# NUC121AE_v1 register map
File version: 1.0
Registers are 32-bit, read-write, reset 0x0 unless marked. A register's access mark holds for its fields unless they carry their own. Offsets are from the block's base; [hi:lo] are bit positions; lines under a group give offsets from that group; {n}, {i} and the like mark numbered series; 'fields as' and 'values as' point back to an identical list.

## CLK — CLK Register Map
Base 0x50000200
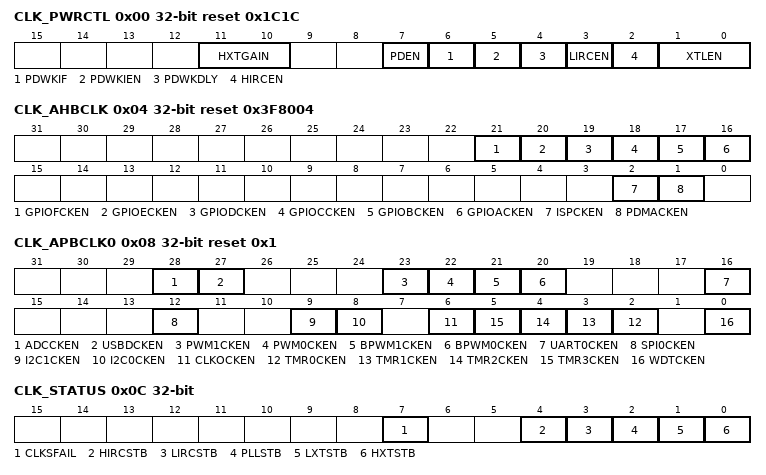
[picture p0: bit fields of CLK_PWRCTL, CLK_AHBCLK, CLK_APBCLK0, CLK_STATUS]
0x00 CLK_PWRCTL reset 0x1C1C — System Power-down Control Register
  [11:10] HXTGAIN — HXT Gain Control Bit (Write Protect). This is a protected register. Please refer to open lock sequence to program it. Gain control is used to enlarge the gain of crystal to make sure crystal work normally. If gain control is enabled, crystal will consume more power than gain control off. Note 1: These bits are write protected. Refer to the SYS_REGLCTL register. Note 2: These bits are over-written by CFGXT1 (CONFIG0[18:17]) after reset.
    0=HXT frequency is lower than from 8 MHz; 1=HXT frequency is from 8 MHz to 12 MHz; 2=HXT frequency is from 12 MHz to 16 MHz; 3=HXT frequency is higher than 16 MHz
  [7] PDEN — System Power-down Enable (Write Protect). When this bit is set to 1, Power-down mode is enabled and chip keeps active till the CPU sleep mode is also active and then the chip enters Power-down mode. When chip wakes up from Power-down mode, this bit is auto cleared. Users need to set this bit again for next Power-down. In Power-down mode, HXT and the HIRC will be disabled in this mode, but LXT and LIRC are not controlled by Power-down mode. In Power-down mode, the PLL and system clock are disabled, and ignored the clock source selection. The clocks of peripheral are not controlled by Power-down mode, if the peripheral clock source is from LXT or LIRC. Note: This bit is write protected. Refer to the SYS_REGLCTL register.
    0=Chip operating normally or chip in idle mode because of WFI command; 1=Chip enters Power-down mode instant or wait CPU sleep command WFI
  [6] PDWKIF — Power-down Mode Wake-up Interrupt Status. Set by "Power-down wake-up event", it indicates that resume from Power-down mode" The flag is set if the EINT0~5, GPIO, USBD, UART0, WDT, BOD, TMR0~3 or I2C0~1 wake-up occurred. Note1: Write 1 to clear the bit to 0. Note2: This bit works only if PDWKIEN (CLK_PWRCTL[5]) set to 1.
  [5] PDWKIEN — Power-down Mode Wake-up Interrupt Enable Bit (Write Protect). Note1: The interrupt will occur when both PDWKIF and PDWKIEN are high. Note2: This bit is write protected. Refer to the SYS_REGLCTL register.
    0=Power-down mode wake-up interrupt Disabled; 1=Power-down mode wake-up interrupt Enabled
  [4] PDWKDLY — Enable the Wake-up Delay Counter (Write Protect). When the chip wakes up from Power-down mode, the clock control will delay certain clock cycles to wait system clock stable. The delayed clock cycle is 4096 clock cycles when chip work at 4~24 MHz external high speed crystal oscillator (HXT), and 512 clock cycles(selected by HIRCSTBS) when chip work at 48 MHz internal high speed RC oscillator (HIRC). Note: This bit is write protected. Refer to the SYS_REGLCTL register.
    0=Clock cycles delay Disabled; 1=Clock cycles delay Enabled
  [3] LIRCEN — LIRC Enable Bit (Write Protect). Note: This bit is write protected. Refer to the SYS_REGLCTL register.
    0=10 kHz internal low speed RC oscillator (LIRC) Disabled; 1=10 kHz internal low speed RC oscillator (LIRC) Enabled
  [2] HIRCEN — HIRC Enable Bit (Write Protect). Note: This bit is write protected. Refer to the SYS_REGLCTL register.
    0=48 MHz internal high speed RC oscillator (HIRC) Disabled; 1=48 MHz internal high speed RC oscillator (HIRC) Enabled
  [1:0] XTLEN — External HXT or LXT Crystal Oscillator Enable Bit (Write Protect). The default clock source is from HIRC. These two bits are default set to "00" and the PF.0 and PF.1 pins are GPIO. Note 1: These bits are write protected. Refer to the SYS_REGLCTL register. Note 2: These bits are over-written by CFOSC (CONFIG0[26]) after reset.
    0=HXT LXT Disabled (default); 1=HXT Enabled; 2=LXT Enabled
0x04 CLK_AHBCLK reset 0x3F8004 — AHB Devices Clock Enable Control Register
  [21] GPIOFCKEN — General Purpose I/O PF Group Clock Enable Bit
    0=GPIO PF group clock Disabled; 1=GPIO PF group clock Enabled
  [20] GPIOECKEN — General Purpose I/O PE Group Clock Enable Bit
    0=GPIO PE group clock Disabled; 1=GPIO PE group clock Enabled
  [19] GPIODCKEN — General Purpose I/O PD Group Clock Enable Bit
    0=GPIO PD group clock Disabled; 1=GPIO PD group clock Enabled
  [18] GPIOCCKEN — General Purpose I/O PC Group Clock Enable Bit
    0=GPIO PC group clock Disabled; 1=GPIO PC group clock Enabled
  [17] GPIOBCKEN — General Purpose I/O PB Group Clock Enable Bit
    0=GPIO PB group clock Disabled; 1=GPIO PB group clock Enabled
  [16] GPIOACKEN — General Purpose I/O PA Group Clock Enable Bit
    0=GPIO PA group clock Disabled; 1=GPIO PA group clock Enabled
  [2] ISPCKEN — Flash ISP Controller Clock Enable Bit
    0=Flash ISP peripheral clock Disabled; 1=Flash ISP peripheral clock Enabled
  [1] PDMACKEN — PDMA Controller Clock Enable Bit
    0=PDMA peripheral clock Disabled; 1=PDMA peripheral clock Enabled
0x08 CLK_APBCLK0 reset 0x1 — APB Devices Clock Enable Control Register 0
  [28] ADCCKEN — Analog-digital-converter (ADC) Clock Enable Bit
    0=ADC clock Disabled; 1=ADC clock Enabled
  [27] USBDCKEN — USB Device Clock Enable Bit
    0=USB Device clock Disabled; 1=USB Device clock Enabled
  [23] PWM1CKEN — PWM1 Clock Enable Bit
    0=PWM1 clock Disabled; 1=PWM1 clock Enabled
  [22] PWM0CKEN — PWM0 Clock Enable Bit
    0=PWM0 clock Disabled; 1=PWM0 clock Enabled
  [21] BPWM1CKEN — BPWM1 Clock Enable Bit
    0=BPWM1 clock Disabled; 1=BPWM1 clock Enabled
  [20] BPWM0CKEN — BPWM0 Clock Enable Bit
    0=BPWM0 clock Disabled; 1=BPWM0 clock Enabled
  [16] UART0CKEN — UART0 Clock Enable Bit
    0=UART0 clock Disabled; 1=UART0 clock Enabled
  [12] SPI0CKEN — SPI0 Clock Enable Bit
    0=SPI0 Clock Disabled; 1=SPI0 Clock Enabled
  [9] I2C1CKEN — I2C1 Clock Enable Bit
    0=I2C1 Clock Disabled; 1=I2C1 Clock Enabled
  [8] I2C0CKEN — I2C0 Clock Enable Bit
    0=I2C0 Clock Disabled; 1=I2C0 Clock Enabled
  [6] CLKOCKEN — CLKO Clock Enable Bit
    0=CLKO Clock Disabled; 1=CLKO Clock Enabled
  [n+2] TMR{n}CKEN (n=0..3) — Timer{n} Clock Enable Bit
    0=Timer{n} Clock Disabled; 1=Timer{n} Clock Enabled
  [0] WDTCKEN — Watchdog Timer Clock Enable Bit (Write Protect). Note: This bit is write protected. Refer to the SYS_REGLCTL register.
    0=Watchdog Timer Clock Disabled; 1=Watchdog Timer Clock Enabled
0x0C CLK_STATUS ro (reset mask 0xFFFFFF00) — Clock Status Monitor Register
  [7] CLKSFAIL — Clock Switching Fail Flag (Read Only). This bit is updated when software switches system clock source. If switch target clock is stable, this bit will be set to 0. If switch target clock is not stable, this bit will be set to 1. Note 1: Clock switch will finish automatically when target clcok is stable even if this bit already set to 1.
    0=Clock switching success; 1=Clock switching failure
  [4] HIRCSTB — HIRC Clock Source Stable Flag (Read Only)
    0=48 MHz internal high speed RC oscillator (HIRC) clock is not stable or disabled; 1=48 MHz internal high speed RC oscillator (HIRC) clock is stabe and enabled
  [3] LIRCSTB — LIRC Clock Source Stable Flag (Read Only)
    0=10 kHz internal low speed RC oscillator (LIRC) clock is not stable or disabled; 1=10 kHz internal low speed RC oscillator (LIRC) clock is stable and enabled
  [2] PLLSTB — Internal PLL Clock Source Stable Flag (Read Only)
    0=Internal PLL clock is not stable or disabled; 1=Internal PLL clock is stable and enabled
  [1] LXTSTB — LXT Clock Source Stable Flag (Read Only)
    0=32.768 kHz external low speed crystal oscillator (LXT) clock is not stable or disabled; 1=32.768 kHz external low speed crystal oscillator (LXT) clock is stabled and enabled
  [0] HXTSTB — HXT Clock Source Stable Flag (Read Only)
    0=4~24 MHz external high speed crystal oscillator (HXT) clock is not stable or disabled; 1=4~24 MHz external high speed crystal oscillator (HXT)clock is stable and enabled
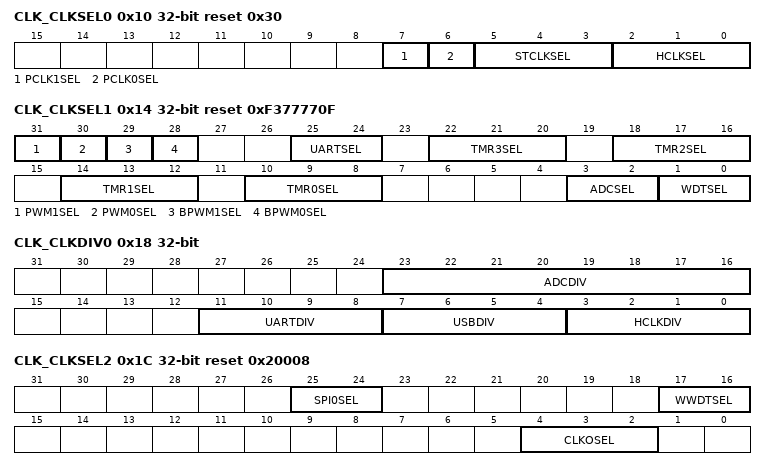
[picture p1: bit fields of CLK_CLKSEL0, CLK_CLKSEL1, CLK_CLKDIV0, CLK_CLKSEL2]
0x10 CLK_CLKSEL0 reset 0x30 (reset mask 0xFFFFFFF0) — Clock Source Select Control Register 0
  [7] PCLK1SEL — PCLK1 Clock Source Selection (Write Protect). Note: This bit is write protected. Refer to the SYS_REGLCTL register.
    0=APB1 BUS clock source from HCLK clock; 1=APB1 BUS clock source from HCLK/2
  [6] PCLK0SEL — PCLK0 Clock Source Selection (Write Protect). Note: This bit is write protected. Refer to the SYS_REGLCTL register.
    0=APB0 BUS clock source from HCLK clock; 1=APB0 BUS clock source from HCLK/2
  [5:3] STCLKSEL — Cortex-M0 SysTick Clock Source Selection (Write Protect). Note: These bits are write protected. Refer to the SYS_REGLCTL register.
    0=Clock source from HXT clock; 1=Clock source from LXT clock; 2=Clock source from HXT/2; 3=Clock source from HCLK/2; 7=Clock source from HIRC/4 (12 MHz)
  [2:0] HCLKSEL — HCLK Clock Source Selection (Write Protect). Before clock switching, the related clock sources (both pre-select and new-select) must be turned on. The default value is reloaded from the value of CFOSC (CONFIG0[26:24]) in user configuration register of Flash controller by any reset. Therefore the default value is either 000b or 111b. Note: These bits are write protected. Refer to the SYS_REGLCTL register.
    0=Clock source from HXT clock; 1=Clock source from LXT clock; 2=Clock source from PLL clock; 3=Clock source from LIRC clock; 4=Clock source from HIRC clock; 5=Clock source from PLL/2; 7=Clock source from HIRC/2(24 MHz)
0x14 CLK_CLKSEL1 reset 0xF377770F — Clock Source Select Control Register 1
  [31] PWM1SEL — PWM1 Clock Source Selection. The peripheral clock source of PWM1 is defined by PWM1SEL.
    0=Clock source from PLL clock; 1=Clock source from PCLK1 clock
  [30] PWM0SEL — PWM0 Clock Source Selection. The peripheral clock source of PWM1 is defined by PWM0SEL.
    0=Clock source from PLL clock; 1=Clock source from PCLK0 clock
  [29] BPWM1SEL — BPWM1 Clock Source Selection. The peripheral clock source of BPWM1 is defined by BPWM1SEL.
    values as PWM1SEL
  [28] BPWM0SEL — BPWM0 Clock Source Selection. The peripheral clock source of BPWM0 is defined by BPWM0SEL.
    values as PWM0SEL
  [25:24] UARTSEL — UART Clock Source Selection
    0=Clock source from HXT clock; 1=Clock source from PLL clock; 2=Clock source from LXT clock; 3=Clock source from HIRC/2 clock
  [22:20] TMR3SEL — TIMER3 Clock Source Selection
    0=Clock source from HXT clock; 1=Clock source from LXT clock; 2=Clock source from PCLK1 clock; 3=Clock source from external clock T3 pin; 5=Clock source from LIRC clock; 7=Clock source from HIRC/2 (24 MHz)
  [18:16] TMR2SEL — TIMER2 Clock Source Selection
    0=Clock source from HXT clock; 1=Clock source from LXT clock; 2=Clock source from PCLK1 clock; 3=Clock source from external clock T2 pin; 5=Clock source from LIRC clock; 7=Clock source from HIRC/2 (24 MHz)
  [14:12] TMR1SEL — TIMER1 Clock Source Selection
    0=Clock source from HXT; 1=Clock source from LXT; 2=Clock source from PCLK0; 3=Clock source from external clock T1 pin; 5=Clock source from LIRC; 7=Clock source from HIRC/2 (24 MHz)
  [10:8] TMR0SEL — TIMER0 Clock Source Selection
    0=Clock source from HXT clock; 1=Clock source from LXT clock; 2=Clock source from PCLK0 clock; 3=Clock source from external clock T0 pin; 5=Clock source from LIRC clock; 7=Clock source from HIRC/2 (24 MHz)
  [3:2] ADCSEL — ADC Peripheral Clock Source Selection
    0=Clock source is from HXT clock; 1=Clock source is from PLL clock; 2=Clock source is from PCLK0 clock; 3=Clock source is from HIRC/2 (24 MHz)
  [1:0] WDTSEL — Watchdog Timer Clock Source Selection (Write Protect). Note: These bits are write protected. Refer to the SYS_REGLCTL register.
    1=Clock source from LXT clock; 2=Clock source from HCLK/2048; 3=Clock source from LIRC clock
0x18 CLK_CLKDIV0 — Clock Divider Number Register 0
  [23:16] ADCDIV — ADC Clock Divide Number From EADC Clock Source
  [11:8] UARTDIV — UART Clock Divide Number From UART Clock Source
  [7:4] USBDIV — USB Clock Divide Number From PLL Clock
  [3:0] HCLKDIV — HCLK Clock Divide Number From HCLK Clock Source
0x1C CLK_CLKSEL2 reset 0x20008 — Clock Source Select Control Register 2
  [25:24] SPI0SEL — SPI0 Clock Source Selection
    0=Clock source from HXT clock; 1=Clock source from PLL clock; 2=Clock source from PCLK0 clock; 3=Clock source from HIRC clock
  [17:16] WWDTSEL — Window Watchdog Timer Clock Source Selection
    2=Clock source from HCLK/2048 clock; 3=Clock source from LIRC clock
  [4:2] CLKOSEL — Clock Divider Clock Source Selection
    0=Clock source from HXT clock; 1=Clock source from LXT clock; 2=Clock source from HCLK clock; 3=Clock source from HIRC/2 clock; 5=Clock source from HIRC clock; 7=Clock source from SOF (USB Start Of Frame) event. (not 50% duty cycle)
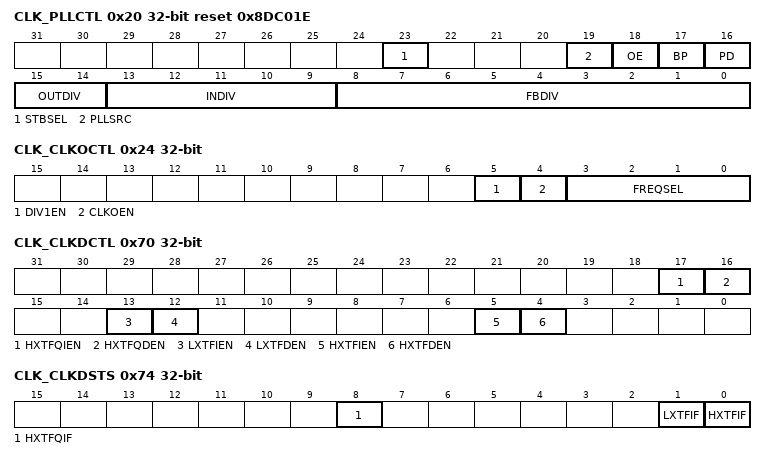
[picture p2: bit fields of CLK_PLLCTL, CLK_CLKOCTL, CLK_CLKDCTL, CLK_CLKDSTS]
0x20 CLK_PLLCTL reset 0x8DC01E — PLL Control Register
  [23] STBSEL — PLL Stable Counter Selection
    0=PLL stable time is 6144 PLL source clock (suitable for source clock is equal to or less than 12MHz); 1=PLL stable time is 12288 PLL source clock (suitable for source clock is larger than 12MHz)
  [19] PLLSRC — PLL Source Clock Selection
    0=PLL source clock from external 4~24 MHz high-speed crystal (HXT); 1=PLL source clock from internal 24 MHz high-speed oscillator (HIRC/2)
  [18] OE — PLL OE (FOUT Enable) Pin Control
    0=PLL FOUT Enabled; 1=PLL FOUT is fixed low
  [17] BP — PLL Bypass Control
    0=PLL is in normal mode (default); 1=PLL clock output is same as PLL input clock FIN
  [16] PD — Power-down Mode. If set the PDEN bit to 1 in CLK_PWRCTL register, the PLL will enter Power-down mode, too.
    0=PLL is in normal mode; 1=PLL is in Power-down mode (default)
  [15:14] OUTDIV — PLL Output Divider Control. Refer to the formulas below the table.
  [13:9] INDIV — PLL Input Divider Control. Refer to the formulas below the table.
  [8:0] FBDIV — PLL Feedback Divider Control. Refer to the formulas below the table.
0x24 CLK_CLKOCTL — Clock Output Control Register
  [5] DIV1EN — Clock Output Divide One Enable Bit
    0=Clock Output will output clock with source frequency divided by FREQSEL; 1=Clock Output will output clock with source frequency
  [4] CLKOEN — Clock Output Enable Bit
    0=Clock Output function Disabled; 1=Clock Output function Enabled
  [3:0] FREQSEL — Clock Output Frequency Selection. The formula of output frequency is. Fin is the input clock frequency. Fout is the frequency of divider output clock. N is the 4-bit value of FREQSEL[3:0].
0x30 CLK_APBCLK1 — APB Devices Clock Enable Control Register 1
  [8] USCI0CKEN — USCI0 Clock Enable Bit
    0=USCI0 clock Disabled; 1=USCI0 clock Enabled
0x34 CLK_CLKSEL3 — Clock Source Select Control Register 3
  [8] USBDSEL — USBD Clock Source Selection (Write Protect). Note: This bit is write protected. Refer to the SYS_REGLCTL register.
    0=Clock source from HIRC; 1=Clock source from PLL clock
0x70 CLK_CLKDCTL — Clock Fail Detector Control Register
  [17] HXTFQIEN — HXT Clock Frequency Monitor Interrupt Enable Bit
    0=4~24 MHz external high speed crystal oscillator (HXT) clock frequency monitor fail interrupt Disabled; 1=4~24 MHz external high speed crystal oscillator (HXT) clock frequency monitor fail interrupt Enabled
  [16] HXTFQDEN — HXT Clock Frequency Monitor Enable Bit
    0=4~24 MHz external high speed crystal oscillator (HXT) clock frequency monitor Disabled; 1=4~24 MHz external high speed crystal oscillator (HXT) clock frequency monitor Enabled
  [13] LXTFIEN — LXT Clock Fail Interrupt Enable Bit
    0=32.768 kHz external low speed crystal oscillator (LXT) clock Fail interrupt Disabled; 1=32.768 kHz external low speed crystal oscillator (LXT) clock Fail interrupt Enabled
  [12] LXTFDEN — LXT Clock Fail Detector Enable Bit
    0=32.768 kHz external low speed crystal oscillator (LXT) clock Fail detector Disabled; 1=32.768 kHz external low speed crystal oscillator (LXT) clock Fail detector Enabled
  [5] HXTFIEN — HXT Clock Fail Interrupt Enable Bit
    0=4~24 MHz external high speed crystal oscillator (HXT)clock Fail interrupt Disabled; 1=4~24 MHz external high speed crystal oscillator (HXT)clock Fail interrupt Enabled
  [4] HXTFDEN — HXT Clock Fail Detector Enable Bit
    0=4~24 MHz external high speed crystal oscillator (HXT) clock Fail detector Disabled; 1=4~24 MHz external high speed crystal oscillator (HXT) clock Fail detector Enabled
0x74 CLK_CLKDSTS — Clock Fail Detector Status Register
  [8] HXTFQIF — HXT Clock Frequency Monitor Interrupt Flag. Note: Write 1 to clear the bit to 0.
    0=4~24 MHz external high speed crystal oscillator (HXT) clock normal; 1=4~24 MHz external high speed crystal oscillator (HXT) clock frequency abnormal
  [1] LXTFIF — LXT Clock Fail Interrupt Flag. Note: Write 1 to clear the bit to 0.
    0=32.768 kHz external low speed crystal oscillator (LXT) clock normal; 1=32.768 kHz external low speed crystal oscillator (LXT) stop
  [0] HXTFIF — HXT Clock Fail Interrupt Flag. Note: Write 1 to clear the bit to 0.
    0=4~24 MHz external high speed crystal oscillator (HXT) clock normal; 1=4~24 MHz external high speed crystal oscillator (HXT) clock stop
0x78 CLK_CDUPB — Clock Frequency Detector Upper Boundary Register
  [9:0] UPERBD — HXT Clock Frequency Detector Upper Boundary. The bits define the high value of frequency monitor window. When HXT frequency monitor value higher than this register, the HXT frequency detect fail interrupt flag will set to 1.
0x7C CLK_CDLOWB — Clock Frequency Detector Low Boundary Register
  [9:0] LOWERBD — HXT Clock Frequency Detector Low Boundary. The bits define the low value of frequency monitor window. When HXT frequency monitor value lower than this register, the HXT frequency detect fail interrupt flag will set to 1.
